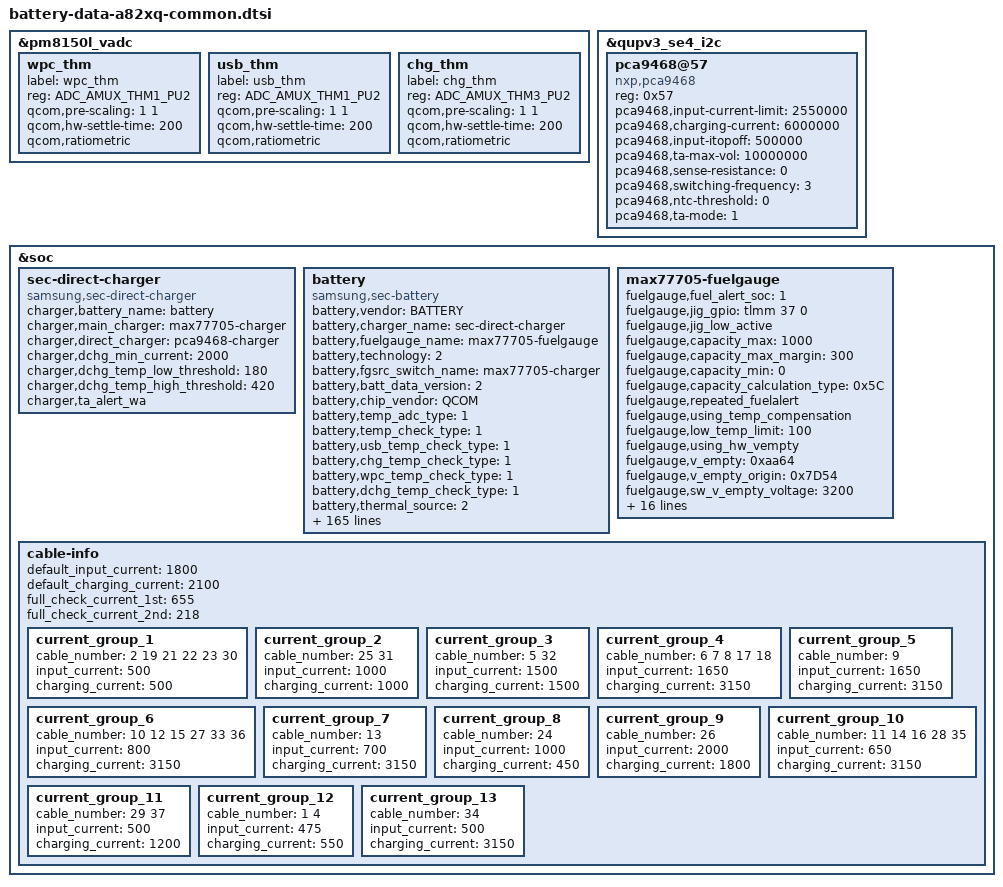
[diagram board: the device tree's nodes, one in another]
/* Copyright (c) 2014, The Linux Foundation. All rights reserved.
 *
 * This program is free software; you can redistribute it and/or modify
 * it under the terms of the GNU General Public License version 2 and
 * only version 2 as published by the Free Software Foundation.
 *
 * This program is distributed in the hope that it will be useful,
 * but WITHOUT ANY WARRANTY; without even the implied warranty of
 * MERCHANTABILITY or FITNESS FOR A PARTICULAR PURPOSE.  See the
 * GNU General Public License for more details.
 */

&pm8150l_vadc {
	wpc_thm { /* AMUX_1 */
		label = "wpc_thm";
		reg = <ADC_AMUX_THM1_PU2>;
		qcom,pre-scaling = <1 1>;
		qcom,hw-settle-time = <200>;
		qcom,ratiometric;
	};
	usb_thm { /* AMUX_1 */
		label = "usb_thm";
		reg = <ADC_AMUX_THM1_PU2>;
		qcom,pre-scaling = <1 1>;
		qcom,hw-settle-time = <200>;
		qcom,ratiometric;
	};
	chg_thm { /* AMUX_3 */
		label = "chg_thm";
		reg = <ADC_AMUX_THM3_PU2>;
		qcom,pre-scaling = <1 1>;
		qcom,hw-settle-time = <200>;
		qcom,ratiometric;
	};
};

&qupv3_se4_i2c {
	status = "okay";

	pca9468@57 {
		compatible = "nxp,pca9468";
		reg = <0x57>;
		pca9468,input-current-limit = <2550000>; /* 2.55A */
		pca9468,charging-current = <6000000>; /* 6A */
		pca9468,input-itopoff = <500000>; /* 500mA */
		pca9468,ta-max-vol = <10000000>; /* 10.0V */
		pca9468,sense-resistance = <0>; /* 5mOhm */
		pca9468,switching-frequency = <3>; /* 980KHz */
		pca9468,ntc-threshold = <0>; /* disable */
		pca9468,ta-mode = <1>; /* 2:1 charging mode */
	};
};

&soc {
	sec-direct-charger {
		status = "okay";
		compatible = "samsung,sec-direct-charger";

		charger,battery_name = "battery";
		charger,main_charger = "max77705-charger";
		charger,direct_charger = "pca9468-charger";

		charger,dchg_min_current = <2000>;
		charger,dchg_temp_low_threshold = <180>;
		charger,dchg_temp_high_threshold = <420>;

		charger,ta_alert_wa;
	};

	battery {
		status = "okay";
		compatible = "samsung,sec-battery";
		pinctrl-names = "default";
		//pinctrl-0 = <&wpc_det_default &wpc_thm_default>;
		battery,vendor = "BATTERY";
		battery,charger_name = "sec-direct-charger";
		battery,fuelgauge_name = "max77705-fuelgauge";
		battery,technology = <2>; /* POWER_SUPPLY_TECHNOLOGY_LION */
		battery,fgsrc_switch_name = "max77705-charger"; /* Fuelgauge voltage source */

		battery,batt_data_version = <2>;

		battery,chip_vendor = "QCOM";
		battery,temp_adc_type = <1>; /* SEC_BATTERY_ADC_TYPE_AP */

		battery,temp_check_type = <1>; /* SEC_BATTERY_TEMP_CHECK_ADC */
		battery,usb_temp_check_type = <1>;
		battery,chg_temp_check_type = <1>;
		battery,wpc_temp_check_type = <1>;
		battery,dchg_temp_check_type = <1>;

		battery,thermal_source = <2>; /* SEC_BATTERY_THERMAL_SOURCE_ADC */
		battery,usb_thermal_source = <2>; /* SEC_BATTERY_THERMAL_SOURCE_ADC */
		battery,chg_thermal_source = <2>; /* SEC_BATTERY_THERMAL_SOURCE_ADC */
		battery,wpc_thermal_source = <2>; /* SEC_BATTERY_THERMAL_SOURCE_ADC */
		battery,dchg_thermal_source = <3>; /* SEC_BATTERY_THERMAL_SOURCE_CHG_ADC */

		battery,polling_time = <10 30 30 30 3600>;

		battery,temp_table_adc = <129433 152130 178676 211115 247675
						290917 341273 399773 466219 542311
						627378 720923 822232 929141 1039327
						1149448 1258163 1359839 1452832 1535932
						1607190 1667246 1716003>;
		battery,temp_table_data = <900 850 800 750 700
						650 600 550 500 450
						400 350 300 250 200
						150 100 50 0 (-50)
						(-100) (-150) (-200)>;

		battery,usb_temp_table_adc = <133671 149351 179065 211894 247533
						290981 341673 395826 446928 509299
						592019 688343 792386 902226 1016500
						1130600 1236332 1339100 1432525 1520566
						1591933 1655016 1711375>;
		battery,usb_temp_table_data = <900 850 800 750 700
						650 600 550 500 450
						400 350 300 250 200
						150 100 50 0 (-50)
						(-100) (-150) (-200)>;

		battery,chg_temp_table_adc = <119658 142614 169333 204574 240592
						283185 332893 390592 456476 531866
						615798 708348 808325 915538 1024923
						1133910 1241490 1341706 1434526 1518154
						1590311 1651286 1699448>;
		battery,chg_temp_table_data = <900 850 800 750 700
						650 600 550 500 450
						400 350 300 250 200
						150 100 50 0 (-50)
						(-100) (-150) (-200)>;

		battery,wpc_temp_table_adc = <146452 163386 192343 224566 259775
						301794 352400 405363 455579 538624
						599156 694398 796863 905449 1018252
						1132309 1236829 1342754 1435726 1520761
						1591976 1658520 1708585>;
		battery,wpc_temp_table_data = <900 850 800 750 700
						650 600 550 500 450
						400 350 300 250 200
						150 100 50 0 (-50)
						(-100) (-150) (-200)>;

		battery,dchg_temp_table_adc = <111435 133722 158355 192372 227562
						268617 316710 373014 436356 509082
						592365 681513 778872 882096 990012
						1094409 1199979 1298511 1387659 1468596
						1537803 1595280 1642200>;
		battery,dchg_temp_table_data = <900 850 800 750 700
						650 600 550 500 450
						400 350 300 250 200
						150 100 50 0 (-50)
						(-100) (-150) (-200)>;

		battery,wireless_cc_cv = <85>;
		//battery,wpc_det = <&pm8150l_gpios 1 GPIO_ACTIVE_HIGH>; /* WPC_DET */
		//battery,wpc_en = <&tlmm 53 0>; /* WPC_EN */
		//battery,mst_pwr_en = <&tlmm 60 0>; /* MST_PWR_EN */
		battery,adc_check_count = <5>;

		battery,cable_check_type = <4>; /* SEC_BATTERY_CABLE_CHECK_PSY */
		battery,cable_source_type = <1>; /* SEC_BATTERY_CABLE_SOURCE_EXTERNAL */
		battery,polling_type = <1>; /* SEC_BATTERY_MONITOR_ALARM */
		battery,monitor_initial_count = <0>;

		battery,battery_check_type = <0>; /* SEC_BATTERY_CHECK_NONE */
		battery,check_count = <0>;
		battery,check_adc_max = <1440>;
		battery,check_adc_min = <0>;

		battery,ovp_uvlo_check_type = <3>; /* SEC_BATTERY_OVP_UVLO_CHGPOLLING */

		battery,temp_check_count = <1>;
		battery,temp_highlimit_threshold_event = <700>;
		battery,temp_highlimit_recovery_event = <680>;
		battery,temp_high_threshold_event = <500>;
		battery,temp_high_recovery_event = <480>;
		battery,temp_low_threshold_event = <0>;
		battery,temp_low_recovery_event = <20>;
		battery,temp_highlimit_threshold_normal = <700>;
		battery,temp_highlimit_recovery_normal = <680>;
		battery,temp_high_threshold_normal = <500>;
		battery,temp_high_recovery_normal = <480>;
		battery,temp_low_threshold_normal = <0>;
		battery,temp_low_recovery_normal = <20>;
		battery,temp_highlimit_threshold_lpm = <700>;
		battery,temp_highlimit_recovery_lpm = <680>;
		battery,temp_high_threshold_lpm = <500>;
		battery,temp_high_recovery_lpm = <480>;
		battery,temp_low_threshold_lpm = <0>;
		battery,temp_low_recovery_lpm = <20>;
		battery,tx_high_threshold = <450>;
		battery,tx_high_recovery = <400>;
		battery,tx_low_threshold = <0>;
		battery,tx_low_recovery = <50>;
		battery,full_check_type = <2>; /* SEC_BATTERY_FULLCHARGED_FG_CURRENT */
		battery,full_check_type_2nd = <2>; /* SEC_BATTERY_FULLCHARGED_FG_CURRENT */
		battery,full_check_count = <1>;
		battery,chg_gpio_full_check = <0>;
		battery,chg_polarity_full_check = <1>;

		battery,chg_high_temp = <500>;
		battery,chg_high_temp_recovery = <440>;
		battery,dchg_high_temp = <490>;
		battery,dchg_high_temp_recovery = <430>;
		battery,dchg_high_batt_temp = <400>;
		battery,dchg_high_batt_temp_recovery = <380>;
		battery,chg_input_limit_current = <1000>;
		battery,chg_charging_limit_current = <1400>;
		battery,dchg_input_limit_current = <1000>;
		battery,dchg_charging_limit_current = <2000>;

		battery,sleep_mode_limit_current = <800>;

		battery,mix_high_temp = <420>;
		battery,mix_high_chg_temp = <500>;
		battery,mix_high_temp_recovery = <390>;

		/* SEC_BATTERY_FULL_CONDITION_NOTIMEFULL | SEC_BATTERY_FULL_CONDITION_VCELL */
		battery,full_condition_type = <9>;
		battery,full_condition_soc = <93>;
		battery,full_condition_vcell = <4330>;

		battery,recharge_check_count = <1>;
		battery,recharge_condition_type = <4>; /* SEC_BATTERY_RECHARGE_CONDITION_VCELL */
		battery,recharge_condition_soc = <98>;
		battery,recharge_condition_vcell = <4310>;

		battery,charging_total_time = <14400>;
		battery,hv_charging_total_time = <10800>;
		battery,normal_charging_total_time = <18000>;
		battery,usb_charging_total_time = <36000>;
		battery,recharging_total_time = <5400>;
		battery,charging_reset_time = <0>;

		battery,chg_float_voltage = <4380>;
		battery,chg_ocp_current = <6200>;
		battery,chg_ocp_dtc = <100>;

		battery,pre_afc_work_delay = <2000>;
		battery,pre_afc_input_current = <500>;
		battery,prepare_ta_delay = <0>; /* msec */

		battery,swelling_high_temp_block = <420>;
		battery,swelling_high_temp_recov = <400>;
		battery,swelling_low_temp_block_1st = <150>;
		battery,swelling_low_temp_recov_1st = <170>;
		battery,swelling_low_temp_block_2nd = <50>;
		battery,swelling_low_temp_recov_2nd = <70>;
		battery,swelling_low_temp_3rd_ctrl;
		battery,swelling_low_temp_block_3rd = <180>;
		battery,swelling_low_temp_recov_3rd = <200>;

		battery,swelling_low_temp_current = <1000>;	/* 0.24C */
		battery,swelling_low_temp_current_2nd = <400>;	/* 0.1C */
		battery,swelling_low_temp_current_3rd = <2850>;	/* 0.72C */
		battery,swelling_low_temp_topoff = <218>;	/* 0.05C */
		battery,swelling_high_temp_current = <1550>;	/* 0.36C */
		battery,swelling_high_temp_topoff = <218>;	/* 0.05C */

		battery,swelling_drop_float_voltage = <4150>;
		battery,swelling_high_rechg_voltage = <4000>;
		battery,swelling_low_rechg_thr = <180>;

		battery,siop_input_limit_current = <1200>;
		battery,siop_charging_limit_current = <1000>;
		battery,siop_hv_input_limit_current = <700>;
		battery,siop_hv_input_limit_current_2nd = <550>;
		battery,siop_hv_charging_limit_current = <1000>;
		battery,siop_apdo_input_limit_current = <1200>;
		battery,siop_apdo_charging_limit_current = <2000>;

		battery,ttf_hv_charge_current = <2700>;
		battery,ttf_dc25_charge_current = <3700>;

		battery,rp_current_rp1 = <500>;
		battery,rp_current_rp2 = <1500>;
		battery,rp_current_rp3 = <3000>;
		battery,rp_current_rdu_rp3 = <2100>;
		battery,rp_current_abnormal_rp3 = <1800>;

		battery,pd_charging_charge_power = <15000>;
		battery,max_charging_current = <3150>;
		battery,max_charging_charge_power = <25000>; /* 25W */

		/* cycle, chg_float_voltage, recharge_condition_vcell, full_condition_vcell, full_condition_soc, step charging condition */
		battery,age_data = <0 4380 4310 4330 93 45
				300 4360 4290 4310 92 45
				400 4340 4270 4290 91 45
				700 4320 4250 4270 90 45
				1000 4270 4200 4220 89 45>;

		battery,health_condition = <
				/* CYCLE ASOC */
				900 75	/* GOOD */
				1200 65 /* NORMAL */
				1500 55 /* AGED */
				>;

		/* step charging option */
		battery,step_charging_type = <0>;

		/* direct step charging option */
		battery,dc_step_chg_type = <0xE9>;
		battery,dc_step_chg_charge_power = <22000>;
		battery,dc_step_chg_step = <3>;
		battery,dc_step_chg_cond_vol = <4115 4240 4380>; /*<25w 3step> STEP_CHARGING_CONDITION_VOLTAGE */
		battery,dc_step_chg_cond_iin = <2040 1835 0>; /* <25w 3step> STEP_CHARGING_CONDITION_INPUT_CURRENT */
		battery,dc_step_chg_iin_check_cnt = <3>;
		battery,dc_step_chg_cond_soc = <20 60 100
										20 60 100
										20 60 100
										20 60 100
										20 60 100>; /* <25w 3step> STEP_CHARGING_CONDITION_SOC */
		battery,dc_step_chg_val_vfloat = <4115 4240 4380>; /* <25w 3step> STEP_CHARGING_CONDITION_FLOAT_VOLTAGE */
		battery,dc_step_chg_val_iout = <5300 4080 3670>; /* <25w 3step> */

		battery,max_input_voltage = <9000>; /* mV */
		battery,max_input_current = <3000>;  /* mA */

		battery,enable_sysovlo_irq;

		battery,standard_curr = <3670>;
		battery,expired_time = <9720>;
		battery,recharging_expired_time = <5400>;

		battery,battery_full_capacity = <4000>;
		battery,cisd_max_voltage_thr = <4430>; /* batttery ovp dettection voltage */
		battery,cisd_alg_index = <8>;
		battery,ignore_cisd_index = <0 0>;
		battery,ignore_cisd_index_d = <0 80>; /* Do not use AFC_FAIL_PER_DAY to DROP_VALUE_PER_DAY */ 

		battery,tx_stop_capacity = <30>;
		battery,tx_minduty_default = <20>;
		battery,tx_minduty_5V = <50>;

		io-channels = <&pm8150l_vadc ADC_AMUX_THM1_PU2>, <&pm8150l_vadc ADC_AMUX_THM3_PU2>, <&pm8150l_vadc ADC_AMUX_THM1_PU2>, <&pm8150l_vadc ADC_AMUX_THM1_PU2>;
		io-channel-names = "adc-temp", "adc-chg-temp", "adc-wpc-temp", "adc-usb-temp";
	};

	max77705-fuelgauge {
		/* for 4500mAh battery */
		status = "okay";
		fuelgauge,fuel_alert_soc = <1>;
		fuelgauge,jig_gpio = <&tlmm 37 0>; /* IFC_SENSE_INT_AP */
		fuelgauge,jig_low_active;
		fuelgauge,capacity_max = <1000>;
		fuelgauge,capacity_max_margin = <300>;
		fuelgauge,capacity_min = <0>;
		fuelgauge,capacity_calculation_type = <0x5C>;
		fuelgauge,repeated_fuelalert;
		fuelgauge,using_temp_compensation;
		fuelgauge,low_temp_limit = <100>;
		fuelgauge,using_hw_vempty;
		fuelgauge,v_empty = <0xaa64>;
		fuelgauge,v_empty_origin = <0x7D54>; /* Empty: 2500mV, Recover: 3360mV */
		fuelgauge,sw_v_empty_voltage = <3200>;
		fuelgauge,sw_v_empty_voltage_cisd = <3100>;
		fuelgauge,sw_v_empty_recover_voltage = <3480>;
		fuelgauge,fg_resistor = <2>;
		fuelgauge,capacity = <0x101e>; /*capacity = fullcapnom = DesignCap*/
		fuelgauge,fg_reset_wa_data = <0x101e 0x3200 0x0407 0x0030 0x1c30>; /* fullcapnom(=capacity), dPacc, dQacc,  rcomp0, tempco */
		fuelgauge,discharge_temp_threshold = <600>;
		fuelgauge,discharge_volt_threshold = <4200>;

		fuelgauge,lost_soc_trig_soc = <1000>; /* 100.0% */
		fuelgauge,lost_soc_trig_d_soc = <20>; /* 2% */
		fuelgauge,lost_soc_trig_scale = <2>; /* 2x */
		fuelgauge,lost_soc_guarantee_soc = <30>; /* 3.0% */
		fuelgauge,lost_soc_min_vol = <3200>; /* 3200mV */

		fuelgauge,ttf_capacity = <3750>;
		fuelgauge,cv_data = <
			2756	800	1608
			2685	810	1561
			2468	820	1503
			2412	830	1446
			2225	840	1395
			2042	850	1318
			1979	860	1255
			1888	870	1193
			1761	880	1120
			1557	890	1033
			1522	900	952
			1425	910	852
			1343	920	751
			1192	930	646
			1104	940	509
			918	950	389
			770	960	225
			711	970	169
			661	980	58
			657	990	29
			416	1000	0>;
	};

/* sec_battery_cable
 *   0	UNKNOWN,
 *   1	NONE,
 *   2	PREPARE_TA,
 *   3	TA,
 *   4	USB,
 *   5	USB_CDP,
 *   6	9V_TA,
 *   7	9V_ERR,
 *   8	9V_UNKNOWN,
 *   9	12V_TA,
 *  10	WIRELESS,
 *  11	HV_WIRELESS,
 *  12	PMA_WIRELESS,
 *  13	WIRELESS_PACK,
 *  14	CABLE_WIRELESS_HV_PACK,
 *  15	WIRELESS_STAND,
 *  16	WIRELESS_HV_STAND,
 *  17	QC20,
 *  18	QC30,
 *  19	PDIC,
 *  20	UARTOFF,
 *  21	OTG,
 *  22	LAN_HUB,
 *  23	POWER_SHARING,
 *  24	HMT_CONNECTED,
 *  25	HMT_CHARGE,
 *  26	HV_TA_CHG_LIMIT,
 *  27	WIRELESS_VEHICLE,
 *  28	WIRELESS_HV_VEHICLE,
 *  29	PREPARE_WIRELESS_HV,
 *  30  TIMEOUT,
 *  31  SMART_OTG,
 *  32  SMART_NOTG,
 *  33  WIRELESS_TX,
 *  34	HV_WIRELESS_20,
 *  35	HV_WIRELESS_20_LIMIT,
 *  36	WIRELESS_FAKE,
 *  37  PREPARE_WIRELESS_20,
 *  38	CABLE_PDIC_APDO,
 *  39	CABLE_MAX,
 */
	cable-info {
		default_input_current = <1800>;
		default_charging_current = <2100>;
		full_check_current_1st = <655>;
		full_check_current_2nd = <218>;

		current_group_1 {
			cable_number = <2 19 21 22 23 30>;
			input_current = <500>;
			charging_current = <500>;
		};
		current_group_2 {
			cable_number = <25 31>;
			input_current = <1000>;
			charging_current = <1000>;
		};
		current_group_3 {
			cable_number = <5 32>;
			input_current = <1500>;
			charging_current = <1500>;
		};
		current_group_4 {
			cable_number = <6 7 8 17 18>;
			input_current = <1650>;
			charging_current = <3150>;
		};
		current_group_5 {
			cable_number = <9>;
			input_current = <1650>;
			charging_current = <3150>;
		};
		current_group_6 {
			cable_number = <10 12 15 27 33 36>;
			input_current = <800>;
			charging_current = <3150>;
		};
		current_group_7 {
			cable_number = <13>;
			input_current = <700>;
			charging_current = <3150>;
		};
		current_group_8 {
			cable_number = <24>;
			input_current = <1000>;
			charging_current = <450>;
		};
		current_group_9 {
			cable_number = <26>;
			input_current = <2000>;
			charging_current = <1800>;
		};
		current_group_10 {
			cable_number = <11 14 16 28 35>;
			input_current = <650>;
			charging_current = <3150>;
		};
		current_group_11 {
			cable_number = <29 37>;
			input_current = <500>;
			charging_current = <1200>;
		};
		current_group_12 {
			cable_number = <1 4>;
			input_current = <475>;
			charging_current = <550>;
		};
		current_group_13 {
			cable_number = <34>;
			input_current = <500>;
			charging_current = <3150>;
		};
	};
};
